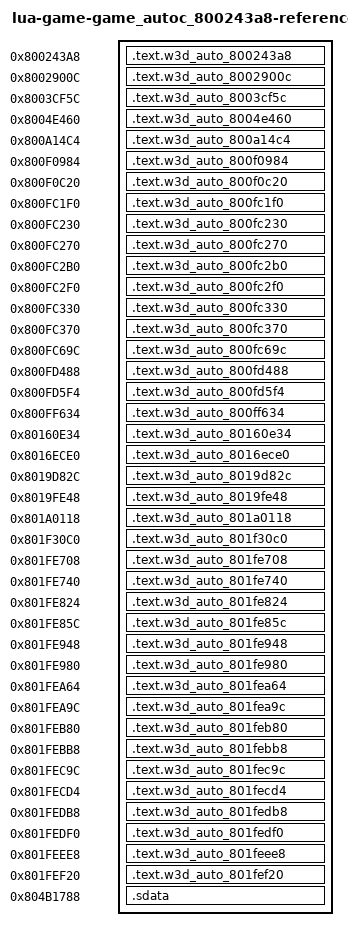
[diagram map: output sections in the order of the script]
/* Generated reference-only placements. All bodies are source-built. */
OUTPUT_FORMAT("elf32-powerpc")
OUTPUT_ARCH(powerpc)
ENTRY(w3d_auto_800243a8)
_SDA_BASE_ = 0x804b2540;
_SDA2_BASE_ = 0x804c2540;
fn_80181640 = 0x80181640;
fn_8018179C = 0x8018179c;
fn_80189704 = 0x80189704;
fn_801F3138 = 0x801f3138;
fn_802CD808 = 0x802cd808;
fn_802DF784 = 0x802df784;
fn_802E0168 = 0x802e0168;
lbl_803777B0 = 0x803777b0;
lbl_803777B4 = 0x803777b4;
SECTIONS {
  .text.w3d_auto_800243a8 0x800243a8 : { *(.text.w3d_auto_800243a8) }
  .text.w3d_auto_8002900c 0x8002900c : { *(.text.w3d_auto_8002900c) }
  .text.w3d_auto_8003cf5c 0x8003cf5c : { *(.text.w3d_auto_8003cf5c) }
  .text.w3d_auto_8004e460 0x8004e460 : { *(.text.w3d_auto_8004e460) }
  .text.w3d_auto_800a14c4 0x800a14c4 : { *(.text.w3d_auto_800a14c4) }
  .text.w3d_auto_800f0984 0x800f0984 : { *(.text.w3d_auto_800f0984) }
  .text.w3d_auto_800f0c20 0x800f0c20 : { *(.text.w3d_auto_800f0c20) }
  .text.w3d_auto_800fc1f0 0x800fc1f0 : { *(.text.w3d_auto_800fc1f0) }
  .text.w3d_auto_800fc230 0x800fc230 : { *(.text.w3d_auto_800fc230) }
  .text.w3d_auto_800fc270 0x800fc270 : { *(.text.w3d_auto_800fc270) }
  .text.w3d_auto_800fc2b0 0x800fc2b0 : { *(.text.w3d_auto_800fc2b0) }
  .text.w3d_auto_800fc2f0 0x800fc2f0 : { *(.text.w3d_auto_800fc2f0) }
  .text.w3d_auto_800fc330 0x800fc330 : { *(.text.w3d_auto_800fc330) }
  .text.w3d_auto_800fc370 0x800fc370 : { *(.text.w3d_auto_800fc370) }
  .text.w3d_auto_800fc69c 0x800fc69c : { *(.text.w3d_auto_800fc69c) }
  .text.w3d_auto_800fd488 0x800fd488 : { *(.text.w3d_auto_800fd488) }
  .text.w3d_auto_800fd5f4 0x800fd5f4 : { *(.text.w3d_auto_800fd5f4) }
  .text.w3d_auto_800ff634 0x800ff634 : { *(.text.w3d_auto_800ff634) }
  .text.w3d_auto_80160e34 0x80160e34 : { *(.text.w3d_auto_80160e34) }
  .text.w3d_auto_8016ece0 0x8016ece0 : { *(.text.w3d_auto_8016ece0) }
  .text.w3d_auto_8019d82c 0x8019d82c : { *(.text.w3d_auto_8019d82c) }
  .text.w3d_auto_8019fe48 0x8019fe48 : { *(.text.w3d_auto_8019fe48) }
  .text.w3d_auto_801a0118 0x801a0118 : { *(.text.w3d_auto_801a0118) }
  .text.w3d_auto_801f30c0 0x801f30c0 : { *(.text.w3d_auto_801f30c0) }
  .text.w3d_auto_801fe708 0x801fe708 : { *(.text.w3d_auto_801fe708) }
  .text.w3d_auto_801fe740 0x801fe740 : { *(.text.w3d_auto_801fe740) }
  .text.w3d_auto_801fe824 0x801fe824 : { *(.text.w3d_auto_801fe824) }
  .text.w3d_auto_801fe85c 0x801fe85c : { *(.text.w3d_auto_801fe85c) }
  .text.w3d_auto_801fe948 0x801fe948 : { *(.text.w3d_auto_801fe948) }
  .text.w3d_auto_801fe980 0x801fe980 : { *(.text.w3d_auto_801fe980) }
  .text.w3d_auto_801fea64 0x801fea64 : { *(.text.w3d_auto_801fea64) }
  .text.w3d_auto_801fea9c 0x801fea9c : { *(.text.w3d_auto_801fea9c) }
  .text.w3d_auto_801feb80 0x801feb80 : { *(.text.w3d_auto_801feb80) }
  .text.w3d_auto_801febb8 0x801febb8 : { *(.text.w3d_auto_801febb8) }
  .text.w3d_auto_801fec9c 0x801fec9c : { *(.text.w3d_auto_801fec9c) }
  .text.w3d_auto_801fecd4 0x801fecd4 : { *(.text.w3d_auto_801fecd4) }
  .text.w3d_auto_801fedb8 0x801fedb8 : { *(.text.w3d_auto_801fedb8) }
  .text.w3d_auto_801fedf0 0x801fedf0 : { *(.text.w3d_auto_801fedf0) }
  .text.w3d_auto_801feee8 0x801feee8 : { *(.text.w3d_auto_801feee8) }
  .text.w3d_auto_801fef20 0x801fef20 : { *(.text.w3d_auto_801fef20) }
  .sdata 0x804b1788 (NOLOAD) : {
    . = 0x0; lbl_804B1788 = .;
    . += 1; }
  /DISCARD/ : { *(.text*) *(.rodata*) *(.data*) *(.bss*) *(.sdata*) *(.sbss*) *(.comment) }
}
